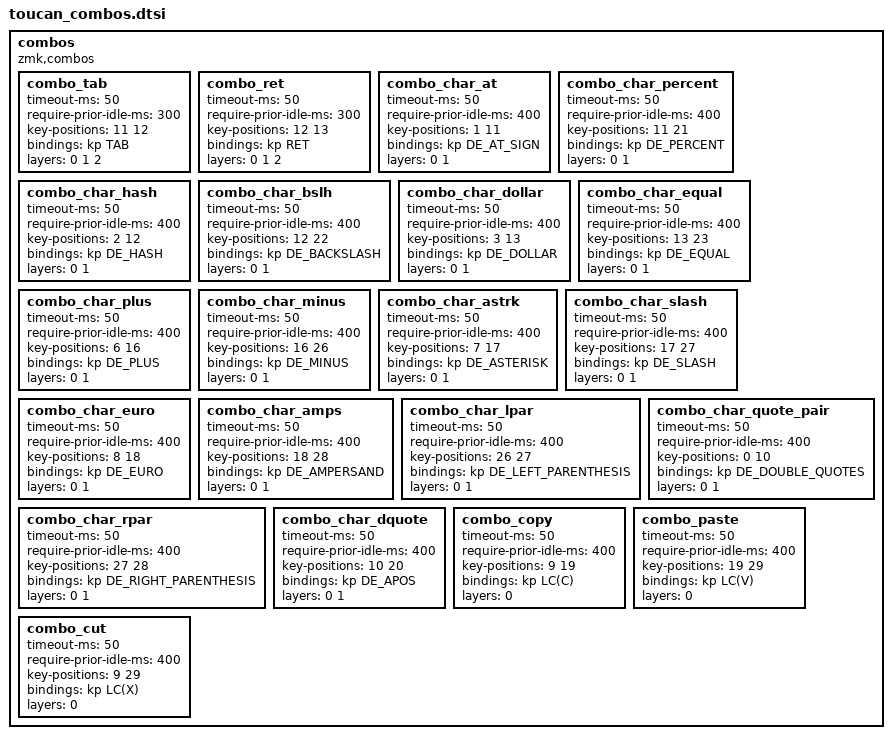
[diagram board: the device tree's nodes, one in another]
// =============================================================================
// Combos for Toucan
// =============================================================================
// All combos are active on layers 0 (Gallium), 1 (Glyph).
// The combos RETURN and TAB are also active on layer 2 (Helm).
//
// Key position reference (5-column layout):
//
//   Left hand                    Right hand
//    0=B   1=L   2=D   3=C   4=V     5=J   6=Y   7=O   8=U   9=?
//   10=N  11=R  12=T  13=S  14=G    15=P  16=H  17=A  18=E  19=I
//   20=X  21=Q  22=M  23=W  24=Z    25=K  26=F  27=,  28=.  29=-
//                30    31    32      33    34    35
//
// Combo layout overview:
//
//   Left vertical (top+home / home+bottom):    Right vertical (top+home / home+bottom):
//     B+N → "    N+X → '                         Y+H → +    H+F → -
//     L+R → @    R+Q → %                         O+A → *    A+, → /
//     D+T → #    T+M → \                         U+E → €    E+. → &
//     C+S → $    S+W → =                         ?+I → Copy  I+- → Paste
//                                                ?+- → Cut (top+bottom stretch)
//
//   Left horizontal (home row):    Right horizontal (bottom row):
//     R+T → Tab    T+S → Return      F+, → (    ,+. → )
//
// Visual combo map:
//
//   Left hand                          Right hand
//    "   @   #   $                      +   *   €  Copy
//    B   L   D   C   V     J   Y   O   U   ?
//    |   |   |   |                  |   |   \   |   /  (Cut)
//    N━━━R━━━T━━━S   G     P   H   A   E   I
//    |   |   |   |                  |   |      Paste
//    X   Q   M   W   Z     K   F━━━,━━━.   -
//   ""   %   \   =                     (   )  (parentheses)
//
//   Tab━━Return (horizontal home row combos)
//
// Timing:
//   timeout-ms = 50ms (both keys must be pressed within this window)
//   require-prior-idle-ms = 400ms (symbols), 300ms (Tab/Return)
// =============================================================================

combos {
    compatible = "zmk,combos";

    // =========================================================================
    // WHITESPACE — Tab and Return
    // =========================================================================

    // R+T (positions 11+12) → Tab
    combo_tab {
        timeout-ms = <50>;
        require-prior-idle-ms = <300>;
        key-positions = <11 12>;
        bindings = <&kp TAB>;
        layers = <0 1 2>;
    };

    // T+S (positions 12+13) → Return
    combo_ret {
        timeout-ms = <50>;
        require-prior-idle-ms = <300>;
        key-positions = <12 13>;
        bindings = <&kp RET>;
        layers = <0 1 2>;
    };

    // =========================================================================
    // SYMBOLS — Vertical combos on the LEFT hand
    // =========================================================================

    // L+R (positions 1+11) → @
    combo_char_at {
        timeout-ms = <50>;
        require-prior-idle-ms = <400>;
        key-positions = <1 11>;
        bindings = <&kp DE_AT_SIGN>;
        layers = <0 1>;
    };

    // R+Q (positions 11+21) → %
    combo_char_percent {
        timeout-ms = <50>;
        require-prior-idle-ms = <400>;
        key-positions = <11 21>;
        bindings = <&kp DE_PERCENT>;
        layers = <0 1>;
    };

    // D+T (positions 2+12) → #
    combo_char_hash {
        timeout-ms = <50>;
        require-prior-idle-ms = <400>;
        key-positions = <2 12>;
        bindings = <&kp DE_HASH>;
        layers = <0 1>;
    };

    // T+M (positions 12+22) → backslash
    combo_char_bslh {
        timeout-ms = <50>;
        require-prior-idle-ms = <400>;
        key-positions = <12 22>;
        bindings = <&kp DE_BACKSLASH>;
        layers = <0 1>;
    };

    // C+S (positions 3+13) → $
    combo_char_dollar {
        timeout-ms = <50>;
        require-prior-idle-ms = <400>;
        key-positions = <3 13>;
        bindings = <&kp DE_DOLLAR>;
        layers = <0 1>;
    };

    // S+W (positions 13+23) → =
    combo_char_equal {
        timeout-ms = <50>;
        require-prior-idle-ms = <400>;
        key-positions = <13 23>;
        bindings = <&kp DE_EQUAL>;
        layers = <0 1>;
    };

    // =========================================================================
    // SYMBOLS — Vertical combos on the RIGHT hand
    // =========================================================================

    // Y+H (positions 6+16) → +
    combo_char_plus {
        timeout-ms = <50>;
        require-prior-idle-ms = <400>;
        key-positions = <6 16>;
        bindings = <&kp DE_PLUS>;
        layers = <0 1>;
    };

    // H+F (positions 16+26) → -
    combo_char_minus {
        timeout-ms = <50>;
        require-prior-idle-ms = <400>;
        key-positions = <16 26>;
        bindings = <&kp DE_MINUS>;
        layers = <0 1>;
    };

    // O+A (positions 7+17) → *
    combo_char_astrk {
        timeout-ms = <50>;
        require-prior-idle-ms = <400>;
        key-positions = <7 17>;
        bindings = <&kp DE_ASTERISK>;
        layers = <0 1>;
    };

    // A+, (positions 17+27) → /
    combo_char_slash {
        timeout-ms = <50>;
        require-prior-idle-ms = <400>;
        key-positions = <17 27>;
        bindings = <&kp DE_SLASH>;
        layers = <0 1>;
    };

    // U+E (positions 8+18) → €
    combo_char_euro {
        timeout-ms = <50>;
        require-prior-idle-ms = <400>;
        key-positions = <8 18>;
        bindings = <&kp DE_EURO>;
        layers = <0 1>;
    };

    // E+. (positions 18+28) → &
    combo_char_amps {
        timeout-ms = <50>;
        require-prior-idle-ms = <400>;
        key-positions = <18 28>;
        bindings = <&kp DE_AMPERSAND>;
        layers = <0 1>;
    };

    // =========================================================================
    // BRACKETS — Horizontal combos on the RIGHT hand bottom row
    // =========================================================================

    // F+, (positions 26+27) → (
    combo_char_lpar {
        timeout-ms = <50>;
        require-prior-idle-ms = <400>;
        key-positions = <26 27>;
        bindings = <&kp DE_LEFT_PARENTHESIS>;
        layers = <0 1>;
    };

    // ,+. (positions 27+28) → )
    combo_char_rpar {
        timeout-ms = <50>;
        require-prior-idle-ms = <400>;
        key-positions = <27 28>;
        bindings = <&kp DE_RIGHT_PARENTHESIS>;
        layers = <0 1>;
    };

    // =========================================================================
    // QUOTES — Vertical combos on the LEFT hand
    // =========================================================================

    // B+N (positions 0+10) → "
    combo_char_quote_pair {
        timeout-ms = <50>;
        require-prior-idle-ms = <400>;
        key-positions = <0 10>;
        bindings = <&kp DE_DOUBLE_QUOTES>;
        layers = <0 1>;
    };

    // N+X (positions 10+20) → '
    combo_char_dquote {
        timeout-ms = <50>;
        require-prior-idle-ms = <400>;
        key-positions = <10 20>;
        bindings = <&kp DE_APOS>;
        layers = <0 1>;
    };

    // =========================================================================
    // CLIPBOARD OPERATIONS — Right hand combos
    // =========================================================================

    // ?+I (positions 9+19) → Copy (Ctrl+C)
    combo_copy {
        timeout-ms = <50>;
        require-prior-idle-ms = <400>;
        key-positions = <9 19>;
        bindings = <&kp LC(C)>;
        layers = <0>;
    };

    // I+- (positions 19+29) → Paste (Ctrl+V)
    combo_paste {
        timeout-ms = <50>;
        require-prior-idle-ms = <400>;
        key-positions = <19 29>;
        bindings = <&kp LC(V)>;
        layers = <0>;
    };

    // ?+- (positions 9+29) → Cut (Ctrl+X)
    combo_cut {
        timeout-ms = <50>;
        require-prior-idle-ms = <400>;
        key-positions = <9 29>;
        bindings = <&kp LC(X)>;
        layers = <0>;
    };

};
